# R40 register map
Vendor: Allwinner; Series: R40; File version: 0.1
CPU: CA7 0, little endian, MPU, FPU, double-precision FPU, 0 interrupt priority bits
Registers are 32-bit, read-write, reset 0x0 unless marked. A register's access mark holds for its fields unless they carry their own. Offsets are from the block's base; [hi:lo] are bit positions; {n}, {i} and the like mark numbered series; 'fields as' and 'values as' point back to an identical list.

## CSI1
Base 0x01C1D000
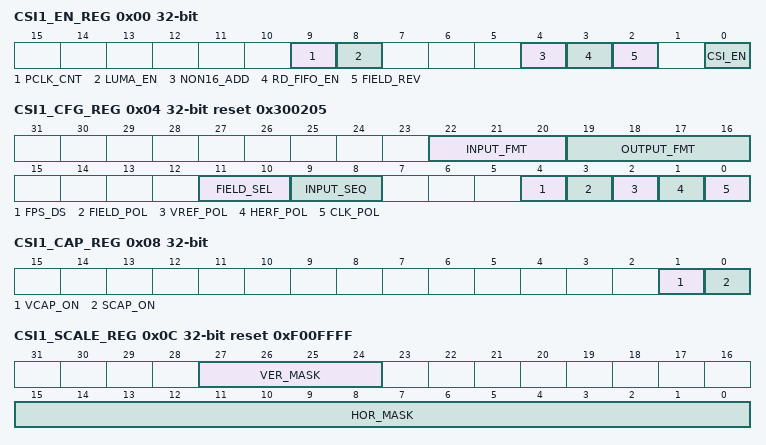
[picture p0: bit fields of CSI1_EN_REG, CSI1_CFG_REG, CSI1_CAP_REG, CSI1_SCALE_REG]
0x00 CSI1_EN_REG — CSI Enable Register
  [9] PCLK_CNT — Pclk count per frame
  [8] LUMA_EN — Luma enable
  [4] NON16_ADD — Non-16 add 0x00
  [3] RD_FIFO_EN — Read fifo [3]fifo enable, fifo address[01c09800~01c09ffc]
  [2] FIELD_REV — CCIR656 field_reverse
  [0] CSI_EN — Enable 0: Reset and disable the CSI module 1: Enable the CSI module
    0=Reset and disable the CSI module; 1=Enable the CSI module
0x04 CSI1_CFG_REG reset 0x300205 — CSI Configuration Register
  [22:20] INPUT_FMT — Input data format 000: RAW stream 001: reserved 010: CCIR656(one channel) 011: YUV422 100: YUV444({R, B, G} or {Pr, Pb, Y}) 101: two channel CCIR656 110: reserved 111: four channel CCIR656
    0=RAW (RAW stream); 2=CCIR656_openingparen_one (CCIR656(one channel)); 3=YUV422; 4=YUV444_openingparen__openingbrace_R (YUV444({R, B, G} or {Pr, Pb, Y})); 5=two (two channel CCIR656); 7=four channel CCIR656
  [19:16] OUTPUT_FMT — Output data format When the input format is set RAW stream 0000: pass-through When the input format is set CCIR656 interface 0000: field planar YCbCr 422 0001: field planar YCbCr 420 0010: frame planar YCbCr 420 0011: frame planar YCbCr 422 0100: field planar YCbCr 422 UV combined 0101: field planar YCbCr 420 UV combined 0110: frame planar YCbCr 420 UV combined 0111: frame planar YCbCr 422 UV combined 1111: interlaced interleaved YCbCr422. In this mode, capturing interlaced input and output the interlaced fields from individual ports. Field 1 data will be written to FIFO0 output buffer and field 2 data will be written to FIFO1 output buffer. 1000: field MB YCbCr 422 1001: field MB YCbCr 420 1010: frame MB YCbCr 420 1011: frame MB YCbCr 422 When the input format is set YUV422 0000: planar YUV 422 0001: planar YUV 420 0100: planar YUV 422 UV combined 0101: planar YUV 420 UV combined 1000: MB YUV 422 1001: MB YUV 420 When the input format is set YUV444 1100: field planar YUV 444 1101: field planar YUV 422 UV combined 1110: frame planar YUV 444 1111: frame planar YUV 422 UV combined
  [11:10] FIELD_SEL — Field selection. Applies to CCIR656 interface only. 00: start capturing with field 1. 01: start capturing with field 2. 10: start capturing with either field. 11: reserved
    0=start_capturing_with_field_1; 1=start_capturing_with_field_2; 2=start_capturing_with_either_field
  [9:8] INPUT_SEQ — Input data sequence, only valid for YUV422 mode. 00: YUYV 01: YVYU 10: UYVY 11: VYUY
    0=YUYV; 1=YVYU; 2=UYVY; 3=VYUY
  [4] FPS_DS — Fps down sample 0: no down sample 1: 1/2 fps, only receives the first frame every 2 frames
    0=no down sample; 1=_1_slash_2 (1/2 fps, only receives the first frame every 2 frames)
  [3] FIELD_POL — Field polarity 0: negative(field=0 indicate odd, field=1 indicate even ) 1: positive(field=1 indicate odd, field=0 indicate even ) This register is not applied to CCIR656 interface.
    0=negative_openingparen_field_equals_0 (negative(field=0 indicate odd, field=1 indicate even )); 1=positive_openingparen_field_equals_1 (positive(field=1 indicate odd, field=0 indicate even ) This register is not applied to CCIR656 interface.)
  [2] VREF_POL — Vref polarity 0: negative 1: positive This register is not applied to CCIR656 interface.
    0=negative; 1=positive This register is not applied to CCIR656 interface
  [1] HERF_POL — Href polarity 0: negative 1: positive This register is not applied to CCIR656 interface.
    values as VREF_POL
  [0] CLK_POL — Data clock type 0: active in rising edge 1: active in falling edge
    0=active_in_rising_edge; 1=active_in_falling_edge
0x08 CSI1_CAP_REG — CSI Capture Control Register
  [1] VCAP_ON — Video capture control: Capture the video image data stream. 0: Disable video capture If video capture is in progress, the CSI stops capturing image data at the end of the current frame, and all of the current frame data is written to output FIFO. 1: Enable video capture The CSI starts capturing image data at the start of the next frame.
    0=Disable video capture If video capture is in progress, the CSI stops capturing image data at the end of the current frame, and all of the current frame data is written to output FIFO; 1=Enable video capture The CSI starts capturing image data at the start of the next frame
  [0] SCAP_ON — Still capture control: Capture a single still image frame. 0: Disable still capture. 1: Enable still capture The CSI module starts capturing image data at the start of the next frame. The CSI module captures only one frame of image data. This bit is self cleared ,and it always reads as a 0.
    0=Disable still capture; 1=Enable still capture The CSI module starts capturing image data at the start of the next frame. The CSI module captures only one frame of image data. This bit is self cleared ,and it always reads as a 0.
0x0C CSI1_SCALE_REG reset 0xF00FFFF — CSI Scale Register
  [27:24] VER_MASK — Vertical (line) mask. Every 4-line is a mask group. Bit 24 masks the first line, bit 25 masks the second line, and so on. Mask bit = 0 means discarding this line data.
  [15:0] HOR_MASK — Horizontal (datastream) mask. Every 16-byte is a mask group. Bit 0 masks the first byte, bit 1 masks the second byte, and so on. Mask bit = 0 means discarding this byte from the datastream.
